# AE402FA0E5597BE0_CM55_HE_View register map
Vendor: Alif Semiconductor; Series: E4; File version: 1.0
CPU: CM55 r1p0, selectable endian, MPU, FPU, double-precision FPU, DSP, VTOR, 8 interrupt priority bits, 1 SAU regions
Registers are 32-bit, read-write, reset 0x0 unless marked. A register's access mark holds for its fields unless they carry their own. Offsets are from the block's base; [hi:lo] are bit positions; {n}, {i} and the like mark numbered series; 'fields as' and 'values as' point back to an identical list.

## CMP0
Base 0x49023000
Same registers: CMP1 0x49024000, CMP2 0x49025000, CMP3 0x49026000
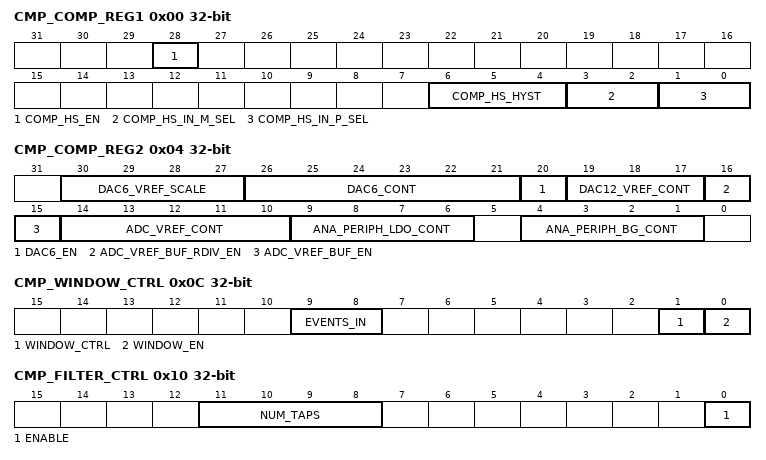
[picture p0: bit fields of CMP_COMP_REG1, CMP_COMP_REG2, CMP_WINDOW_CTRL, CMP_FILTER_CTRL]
0x00 CMP_COMP_REG1 — CMP Control Register 1
  [28] COMP_HS_EN — Enables High-Speed CMP:
    0=Disable; 1=Enable
  [6:4] COMP_HS_HYST — Sets CMP hysteresis level. 6-mV steps.
    0=0 mV; 7=45 mV
  [3:2] COMP_HS_IN_M_SEL — Selects input to negative terminal of CMP:
    0=VREF_IN0 pin; 1=VREF_IN1 pin; 2=Internal Vref; 3=DAC6
  [1:0] COMP_HS_IN_P_SEL — Selects input to positive terminal of CMP:
    {v}=CMPx_IN{v} pin (v=0..3)
0x04 CMP_COMP_REG2 — CMP Control Register 2
  [30:27] DAC6_VREF_SCALE — Allows you to scale the input reference to the DAC6. Step Size = 1/16
    0=1x; 15=2x
  [26:21] DAC6_CONT — This is the output of DAC6 programmable reference voltage. DAC6 Output = (DAC6_VREF_SCALE x DAC6_CONT) / 64
  [20] DAC6_EN — DAC6 Enable. DAC6 takes an input reference and generates a 6-bit programmable output voltage reference.
  [19:17] DAC12_VREF_CONT — Voltage reference values for DAC12
    0=Val_0b000 (0.500 V); 1=Val_0b001 (0.667 V); 2=Val_0b010 (0.667 V); 3=Val_0b011 (0.750 V); 4=Val_0b100 (0.750 V (Default)); 5=Val_0b101 (0.800 V); 6=Val_0b110 (0.800 V); 7=Val_0b111 (0.833 V)
  [16] ADC_VREF_BUF_RDIV_EN — ADC Vref divider enable
    0=Vref = 1.8 V; 1=Vref = 1.5 V
  [15] ADC_VREF_BUF_EN — ADC Vref buffer enable. Turn off if external VREF is connected.
    0=ADC Vref is off; 1=ADC Vref is on
  [14:10] ADC_VREF_CONT — Control for ADC Vref (desired 1.8 V): 1.8 V +- 100 mV, where: Step size = 7 mV
    0=Val_0b00000 (-100 mV); 31=Val_0b11111 (100 mV); 16=Val_0b10000 (1.8 V = Default (0x10))
  [9:6] ANA_PERIPH_LDO_CONT — Analog peripheral LDO (LDO-5) output voltage (VDD_ANA): Step: 20 mV
    0=Val_0b0000 (1.6 V); 15=Val_0b1111 (1.9 V); 10=Val_0b1010 (1.8 V = Default (0xA))
  [4:1] ANA_PERIPH_BG_CONT — Calibration for analog peripherals precision bandgap (desired 1.2 V): Step: 6 mV
    0=Val_0b0000 (1.140 V); 15=Val_0b1111 (1.233 V); 10=Val_0b1010 (1.200 V = Default (0xA))
0x08 CMP_POLARITY_CTRL — CMP Polarity Control Register
  [0] POLARITY_CTRL — If = 0x1, invert the value of CMP_OUT (comparison result) before processing.
0x0C CMP_WINDOW_CTRL — CMP Window Control Register
  [9:8] EVENTS_IN — Selects which of the 4 inputs will control the processing window.
  [1] WINDOW_CTRL — Window function control bit. Note: Bits WINDOW_CTRL and WINDOW_EN must be both set to use windowing function.
    0=Continuously process comparator inputs; 1=Use the EVENTS_IN bit field setting. Selected input will control when to look at comparator inputs.
  [0] WINDOW_EN — Window function enable bit. Note: Bits WINDOW_CTRL and WINDOW_EN must be both set to use windowing function.
    values as WINDOW_CTRL
0x10 CMP_FILTER_CTRL — CMP Filter Control Register
  [11:8] NUM_TAPS — Number of filter taps, 2-8 taps.
  [0] ENABLE — Filtering function enable bit.
0x14 CMP_PRESCALER_CTRL — CMP Prescaler Control Register
  [5:0] PRESCALER_CTRL — Number of clocks between updating taps with new comparator input.
0x18 CMP_STATUS ro
  [0] CMP_VALUE — Current value of the input comparator value from the PMU after synchronization.
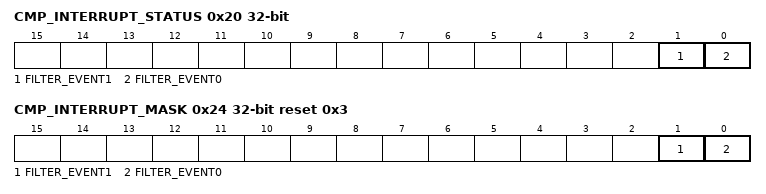
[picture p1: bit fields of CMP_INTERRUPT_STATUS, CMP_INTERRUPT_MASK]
0x20 CMP_INTERRUPT_STATUS wo — CMP Interrupt Status and Clear Register
  [1] FILTER_EVENT1 write-1-clears — FILTER_EVENT1 interrupt status and clear. When read as 1: Filter event has occurred for the programmed number of taps, with a transition on the input from HIGH to LOW. Write 1 to clear.
  [0] FILTER_EVENT0 write-1-clears — FILTER_EVENT0 interrupt status and clear. When read as 1: Filter event has occurred for the programmed number of taps, with a transition on the input from LOW to HIGH. Write 1 to clear.
0x24 CMP_INTERRUPT_MASK reset 0x3
  [1] FILTER_EVENT1 — Mask for the FILTER_EVENT1 interrupt. Note: By default, interrupt mask is set. Mask must be cleared to allow interrupt to be driven out.
    0=Clear mask; 1=Set mask
  [0] FILTER_EVENT0 — Mask for the FILTER_EVENT0 interrupt. Note: By default, interrupt mask is set. Mask must be cleared to allow interrupt to be driven out.
    0=Clear mask; 1=Set mask
